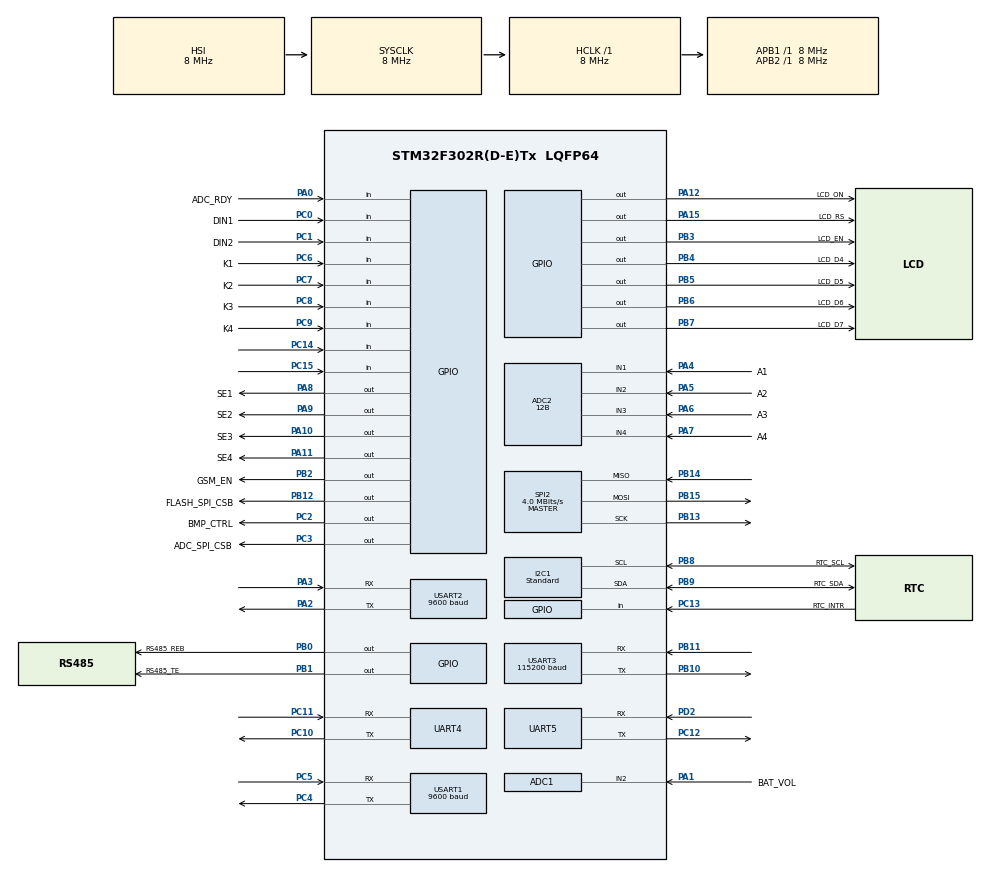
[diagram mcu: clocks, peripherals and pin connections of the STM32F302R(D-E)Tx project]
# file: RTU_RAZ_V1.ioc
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ADC1.Channel-0\#ChannelRegularConversion=ADC_CHANNEL_2
ADC1.ClockPrescaler=ADC_CLOCK_ASYNC_DIV1
ADC1.ContinuousConvMode=DISABLE
ADC1.DMAContinuousRequests=DISABLE
ADC1.DataAlign=ADC_DATAALIGN_RIGHT
ADC1.DiscontinuousConvMode=DISABLE
ADC1.EOCSelection=ADC_EOC_SINGLE_CONV
ADC1.EnableAnalogWatchDog1=false
ADC1.EnableAnalogWatchDog2=false
ADC1.EnableAnalogWatchDog3=false
ADC1.EnableInjectedConversion=ENABLE
ADC1.EnableRegularConversion=ENABLE
ADC1.ExternalTrigConv=ADC_SOFTWARE_START
ADC1.ExternalTrigConvEdge=ADC_EXTERNALTRIGCONVEDGE_NONE
ADC1.InjNumberOfConversion=0
ADC1.LowPowerAutoWait=DISABLE
ADC1.NbrOfConversion=1
ADC1.NbrOfConversionFlag=1
ADC1.Offset-0\#ChannelRegularConversion=0
ADC1.OffsetNumber-0\#ChannelRegularConversion=ADC_OFFSET_NONE
ADC1.Overrun=ADC_OVR_DATA_OVERWRITTEN
ADC1.Rank-0\#ChannelRegularConversion=1
ADC1.Resolution=ADC_RESOLUTION_12B
ADC1.SamplingTime-0\#ChannelRegularConversion=ADC_SAMPLETIME_1CYCLE_5
ADC1.ScanConvMode=ADC_SCAN_DISABLE
ADC1.master=1
ADC2.Channel-0\#ChannelRegularConversion=ADC_CHANNEL_1
ADC2.ClockPrescaler=ADC_CLOCK_ASYNC_DIV1
ADC2.ContinuousConvMode=DISABLE
ADC2.DMAContinuousRequests=DISABLE
ADC2.DataAlign=ADC_DATAALIGN_RIGHT
ADC2.DiscontinuousConvMode=DISABLE
ADC2.EOCSelection=ADC_EOC_SINGLE_CONV
ADC2.EnableAnalogWatchDog1=false
ADC2.EnableAnalogWatchDog2=false
ADC2.EnableAnalogWatchDog3=false
ADC2.EnableInjectedConversion=ENABLE
ADC2.EnableRegularConversion=ENABLE
ADC2.ExternalTrigConv=ADC_SOFTWARE_START
ADC2.ExternalTrigConvEdge=ADC_EXTERNALTRIGCONVEDGE_NONE
ADC2.InjNumberOfConversion=0
ADC2.LowPowerAutoWait=DISABLE
ADC2.NbrOfConversion=1
ADC2.NbrOfConversionFlag=1
ADC2.Offset-0\#ChannelRegularConversion=0
ADC2.OffsetNumber-0\#ChannelRegularConversion=ADC_OFFSET_NONE
ADC2.Overrun=ADC_OVR_DATA_OVERWRITTEN
ADC2.Rank-0\#ChannelRegularConversion=1
ADC2.Resolution=ADC_RESOLUTION_12B
ADC2.SamplingTime-0\#ChannelRegularConversion=ADC_SAMPLETIME_1CYCLE_5
ADC2.ScanConvMode=ADC_SCAN_DISABLE
FREERTOS.Tasks01=defaultTask,0,128,StartDefaultTask,Default,NULL,Dynamic,NULL,NULL;CommonTask,0,128,StartCommonTask,Default,NULL,Dynamic,NULL,NULL;GsmTask,0,128,StartGsmTask,Default,NULL,Dynamic,NULL,NULL
I2C1.I2C_Speed_Mode=I2C_Standard
I2C1.Timing=0x2000090E
Mcu.Family=STM32F3
Mcu.Name=STM32F302R(D-E)Tx
Mcu.Package=LQFP64
NVIC.PriorityGroup=NVIC_PRIORITYGROUP_4
NVIC.TIM1_UP_TIM16_IRQn=true\:0\:0\:false\:false\:true\:false\:false
NVIC.TimeBase=TIM1_UP_TIM16_IRQn
NVIC.TimeBaseIP=TIM16
PA0.GPIO_Label=ADC_RDY
PA0.Signal=GPIO_Input
PA1.GPIO_Label=BAT_VOL
PA1.Signal=SharedAnalog_PA1
PA10.GPIO_Label=SE3
PA10.Signal=GPIO_Output
PA11.GPIO_Label=SE4
PA11.Signal=GPIO_Output
PA12.GPIO_Label=LCD_ON
PA12.Signal=GPIO_Output
PA13.Mode=Serial_Wire
PA13.Signal=SYS_JTMS-SWDIO
PA14.Mode=Serial_Wire
PA14.Signal=SYS_JTCK-SWCLK
PA15.GPIO_Label=LCD_RS
PA15.Signal=GPIO_Output
PA2.Mode=Asynchronous
PA2.Signal=USART2_TX
PA3.Mode=Asynchronous
PA3.Signal=USART2_RX
PA4.GPIO_Label=A1
PA4.Signal=SharedAnalog_PA4
PA5.GPIO_Label=A2
PA5.Signal=SharedAnalog_PA5
PA6.GPIO_Label=A3
PA6.Signal=SharedAnalog_PA6
PA7.GPIO_Label=A4
PA7.Signal=SharedAnalog_PA7
PA8.GPIO_Label=SE1
PA8.Signal=GPIO_Output
PA9.GPIO_Label=SE2
PA9.Signal=GPIO_Output
PB0.GPIO_Label=RS485_REB
PB0.Signal=GPIO_Output
PB1.GPIO_Label=RS485_TE
PB1.Signal=GPIO_Output
PB10.Mode=Asynchronous
PB10.Signal=USART3_TX
PB11.Mode=Asynchronous
PB11.Signal=USART3_RX
PB12.GPIO_Label=FLASH_SPI_CSB
PB12.Signal=GPIO_Output
PB13.Mode=Full_Duplex_Master
PB13.Signal=SPI2_SCK
PB14.Mode=Full_Duplex_Master
PB14.Signal=SPI2_MISO
PB15.Mode=Full_Duplex_Master
PB15.Signal=SPI2_MOSI
PB2.GPIO_Label=GSM_EN
PB2.GPIO_ModeDefaultOutputPP=GPIO_MODE_OUTPUT_OD
PB2.GPIO_Speed=GPIO_SPEED_FREQ_LOW
PB2.PinState=GPIO_PIN_SET
PB2.Signal=GPIO_Output
PB3.GPIO_Label=LCD_EN
PB3.GPIO_ModeDefaultOutputPP=GPIO_MODE_OUTPUT_PP
PB3.Signal=GPIO_Output
PB4.GPIO_Label=LCD_D4
PB4.Signal=GPIO_Output
PB5.GPIO_Label=LCD_D5
PB5.Signal=GPIO_Output
PB6.GPIO_Label=LCD_D6
PB6.Signal=GPIO_Output
PB7.GPIO_Label=LCD_D7
PB7.Signal=GPIO_Output
PB8.GPIO_Label=RTC_SCL
PB8.Mode=I2C
PB8.Signal=I2C1_SCL
PB9.GPIO_Label=RTC_SDA
PB9.Mode=I2C
PB9.Signal=I2C1_SDA
PC0.GPIO_Label=DIN1
PC0.GPIO_PuPd=GPIO_PULLUP
PC0.Signal=GPIO_Input
PC1.GPIO_Label=DIN2
PC1.GPIO_PuPd=GPIO_PULLUP
PC1.Signal=GPIO_Input
PC10.Mode=Asynchronous
PC10.Signal=UART4_TX
PC11.Mode=Asynchronous
PC11.Signal=UART4_RX
PC12.Mode=Asynchronous
PC12.Signal=UART5_TX
PC13.GPIO_Label=RTC_INTR
PC13.GPIO_PuPd=GPIO_PULLUP
PC13.Signal=GPIO_Input
PC14-OSC32_IN.Signal=GPIO_Input
PC15-OSC32_OUT.Signal=GPIO_Input
PC2.GPIO_Label=BMP_CTRL
PC2.Signal=GPIO_Output
PC3.GPIO_Label=ADC_SPI_CSB
PC3.Signal=GPIO_Output
PC4.Mode=Asynchronous
PC4.Signal=USART1_TX
PC5.Mode=Asynchronous
PC5.Signal=USART1_RX
PC6.GPIO_Label=K1
PC6.GPIO_PuPd=GPIO_PULLUP
PC6.Signal=GPIO_Input
PC7.GPIO_Label=K2
PC7.GPIO_PuPd=GPIO_PULLUP
PC7.Signal=GPIO_Input
PC8.GPIO_Label=K3
PC8.GPIO_PuPd=GPIO_PULLUP
PC8.Signal=GPIO_Input
PC9.GPIO_Label=K4
PC9.GPIO_PuPd=GPIO_PULLUP
PC9.Signal=GPIO_Input
PD2.Mode=Asynchronous
PD2.Signal=UART5_RX
ProjectManager.HeapSize=0x200
ProjectManager.StackSize=0x400
ProjectManager.TargetToolchain=TrueSTUDIO
RCC.AHBFreq_Value=8000000
RCC.APB1Freq_Value=8000000
RCC.APB1TimFreq_Value=8000000
RCC.APB2Freq_Value=8000000
RCC.APB2TimFreq_Value=8000000
RCC.CortexFreq_Value=8000000
RCC.HCLKFreq_Value=8000000
RCC.HSE_VALUE=8000000
RCC.HSI_VALUE=8000000
RCC.LSE_VALUE=32768
RCC.SYSCLKFreq_VALUE=8000000
RCC.USBFreq_Value=16000000
SH.SharedAnalog_PA1.0=GPIO_Analog
SH.SharedAnalog_PA1.1=ADC1_IN2,IN2-Single-Ended
SH.SharedAnalog_PA4.0=GPIO_Analog
SH.SharedAnalog_PA4.1=ADC2_IN1,IN1-Single-Ended
SH.SharedAnalog_PA5.0=GPIO_Analog
SH.SharedAnalog_PA5.1=ADC2_IN2,IN2-Single-Ended
SH.SharedAnalog_PA6.0=GPIO_Analog
SH.SharedAnalog_PA6.1=ADC2_IN3,IN3-Single-Ended
SH.SharedAnalog_PA7.0=GPIO_Analog
SH.SharedAnalog_PA7.1=ADC2_IN4,IN4-Single-Ended
SPI2.CalculateBaudRate=4.0 MBits/s
SPI2.Direction=SPI_DIRECTION_2LINES
SPI2.Mode=SPI_MODE_MASTER
SPI2.VirtualType=VM_MASTER
USART1.BaudRate=9600
USART1.VirtualMode-Asynchronous=VM_ASYNC
USART2.BaudRate=9600
USART2.VirtualMode-Asynchronous=VM_ASYNC
USART3.BaudRate=115200
USART3.VirtualMode-Asynchronous=VM_ASYNC
VP_ADC1_TempSens_Input.Mode=IN-TempSens
VP_FREERTOS_VS_ENABLE.Mode=Enabled
VP_IWDG_VS_IWDG.Mode=IWDG_Activate
VP_SYS_VS_tim16.Mode=TIM16
board=custom

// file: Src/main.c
/**
  ******************************************************************************
  * @file           : main.c
  * @brief          : Main program body
  ******************************************************************************
  * This notice applies to any and all portions of this file
  * that are not between comment pairs USER CODE BEGIN and
  * USER CODE END. Other portions of this file, whether
  * inserted by the user or by software development tools
  * are owned by their respective copyright owners.
  *
  * Copyright (c) 2018 STMicroelectronics International N.V.
  * All rights reserved.
  *
  * Redistribution and use in source and binary forms, with or without
  * modification, are permitted, provided that the following conditions are met:
  *
  * 1. Redistribution of source code must retain the above copyright notice,
  *    this list of conditions and the following disclaimer.
  * 2. Redistributions in binary form must reproduce the above copyright notice,
  *    this list of conditions and the following disclaimer in the documentation
  *    and/or other materials provided with the distribution.
  * 3. Neither the name of STMicroelectronics nor the names of other
  *    contributors to this software may be used to endorse or promote products
  *    derived from this software without specific written permission.
  * 4. This software, including modifications and/or derivative works of this
  *    software, must execute solely and exclusively on microcontroller or
  *    microprocessor devices manufactured by or for STMicroelectronics.
  * 5. Redistribution and use of this software other than as permitted under
  *    this license is void and will automatically terminate your rights under
  *    this license.
  *
  * THIS SOFTWARE IS PROVIDED BY STMICROELECTRONICS AND CONTRIBUTORS "AS IS"
  * AND ANY EXPRESS, IMPLIED OR STATUTORY WARRANTIES, INCLUDING, BUT NOT
  * LIMITED TO, THE IMPLIED WARRANTIES OF MERCHANTABILITY, FITNESS FOR A
  * PARTICULAR PURPOSE AND NON-INFRINGEMENT OF THIRD PARTY INTELLECTUAL PROPERTY
  * RIGHTS ARE DISCLAIMED TO THE FULLEST EXTENT PERMITTED BY LAW. IN NO EVENT
  * SHALL STMICROELECTRONICS OR CONTRIBUTORS BE LIABLE FOR ANY DIRECT, INDIRECT,
  * INCIDENTAL, SPECIAL, EXEMPLARY, OR CONSEQUENTIAL DAMAGES (INCLUDING, BUT NOT
  * LIMITED TO, PROCUREMENT OF SUBSTITUTE GOODS OR SERVICES; LOSS OF USE, DATA,
  * OR PROFITS; OR BUSINESS INTERRUPTION) HOWEVER CAUSED AND ON ANY THEORY OF
  * LIABILITY, WHETHER IN CONTRACT, STRICT LIABILITY, OR TORT (INCLUDING
  * NEGLIGENCE OR OTHERWISE) ARISING IN ANY WAY OUT OF THE USE OF THIS SOFTWARE,
  * EVEN IF ADVISED OF THE POSSIBILITY OF SUCH DAMAGE.
  *
  ******************************************************************************
  */
#include "main.h"
#include "stm32f3xx_hal.h"
#include "cmsis_os.h"
#include "adc.h"
#include "i2c.h"
#include "iwdg.h"
#include "spi.h"
#include "usart.h"
#include "gpio.h"

/* USER CODE BEGIN Includes */
#include "common.h"
/* USER CODE END Includes */

/* USER CODE BEGIN PV */
/* Private variables ---------------------------------------------------------*/

/* USER CODE END PV */

void SystemClock_Config(void);
void MX_FREERTOS_Init(void);

/* USER CODE BEGIN PFP */
/* Private function prototypes -----------------------------------------------*/

/* USER CODE END PFP */

int main(void)
{

  /* MCU Configuration----------------------------------------------------------*/

  /* Reset of all peripherals, Initializes the Flash interface and the Systick. */
  HAL_Init();

  /* Configure the system clock */
  SystemClock_Config();

  /* Initialize all configured peripherals */
  MX_GPIO_Init();
  MX_IWDG_Init();
  MX_SPI2_Init();
  MX_UART4_Init();
  MX_UART5_Init();
  MX_USART1_UART_Init();
  MX_USART2_UART_Init();
  MX_USART3_UART_Init();
  MX_I2C1_Init();
  MX_ADC1_Init();
  MX_ADC2_Init();

  /* Call init function for freertos objects (in freertos.c) */
  MX_FREERTOS_Init();

  /* Start scheduler */
  osKernelStart();

  /* We should never get here as control is now taken by the scheduler */

  /* Infinite loop */
  while (1)
  {

  }

}

void SystemClock_Config(void)
{

  RCC_OscInitTypeDef RCC_OscInitStruct;
  RCC_ClkInitTypeDef RCC_ClkInitStruct;
  RCC_PeriphCLKInitTypeDef PeriphClkInit;

    /**Initializes the CPU, AHB and APB busses clocks
    */
  RCC_OscInitStruct.OscillatorType = RCC_OSCILLATORTYPE_HSI|RCC_OSCILLATORTYPE_LSI;
  RCC_OscInitStruct.HSIState = RCC_HSI_ON;
  RCC_OscInitStruct.HSICalibrationValue = 16;
  RCC_OscInitStruct.LSIState = RCC_LSI_ON;
  RCC_OscInitStruct.PLL.PLLState = RCC_PLL_ON;
  RCC_OscInitStruct.PLL.PLLSource = RCC_PLLSOURCE_HSI;
  RCC_OscInitStruct.PLL.PLLMUL = RCC_PLL_MUL2;
  RCC_OscInitStruct.PLL.PREDIV = RCC_PREDIV_DIV1;
  if (HAL_RCC_OscConfig(&RCC_OscInitStruct) != HAL_OK)
  {
    _Error_Handler(__FILE__, __LINE__);
  }

    /**Initializes the CPU, AHB and APB busses clocks
    */
  RCC_ClkInitStruct.ClockType = RCC_CLOCKTYPE_HCLK|RCC_CLOCKTYPE_SYSCLK
                              |RCC_CLOCKTYPE_PCLK1|RCC_CLOCKTYPE_PCLK2;
  RCC_ClkInitStruct.SYSCLKSource = RCC_SYSCLKSOURCE_HSI;
  RCC_ClkInitStruct.AHBCLKDivider = RCC_SYSCLK_DIV1;
  RCC_ClkInitStruct.APB1CLKDivider = RCC_HCLK_DIV1;
  RCC_ClkInitStruct.APB2CLKDivider = RCC_HCLK_DIV1;

  if (HAL_RCC_ClockConfig(&RCC_ClkInitStruct, FLASH_LATENCY_0) != HAL_OK)
  {
    _Error_Handler(__FILE__, __LINE__);
  }

  PeriphClkInit.PeriphClockSelection = RCC_PERIPHCLK_USART1|RCC_PERIPHCLK_USART2
                              |RCC_PERIPHCLK_USART3|RCC_PERIPHCLK_UART4
                              |RCC_PERIPHCLK_UART5|RCC_PERIPHCLK_I2C1
                              |RCC_PERIPHCLK_ADC12;
  PeriphClkInit.Usart1ClockSelection = RCC_USART1CLKSOURCE_PCLK2;
  PeriphClkInit.Usart2ClockSelection = RCC_USART2CLKSOURCE_PCLK1;
  PeriphClkInit.Usart3ClockSelection = RCC_USART3CLKSOURCE_PCLK1;
  PeriphClkInit.Uart4ClockSelection = RCC_UART4CLKSOURCE_PCLK1;
  PeriphClkInit.Uart5ClockSelection = RCC_UART5CLKSOURCE_PCLK1;
  PeriphClkInit.Adc12ClockSelection = RCC_ADC12PLLCLK_DIV1;
  PeriphClkInit.I2c1ClockSelection = RCC_I2C1CLKSOURCE_HSI;
  if (HAL_RCCEx_PeriphCLKConfig(&PeriphClkInit) != HAL_OK)
  {
    _Error_Handler(__FILE__, __LINE__);
  }

    /**Configure the Systick interrupt time
    */
  HAL_SYSTICK_Config(HAL_RCC_GetHCLKFreq()/1000);

    /**Configure the Systick
    */
  HAL_SYSTICK_CLKSourceConfig(SYSTICK_CLKSOURCE_HCLK);

  /* SysTick_IRQn interrupt configuration */
  HAL_NVIC_SetPriority(SysTick_IRQn, 15, 0);
}

void HAL_TIM_PeriodElapsedCallback(TIM_HandleTypeDef *htim)
{
  if (htim->Instance == TIM16) {
    HAL_IncTick();
  }
}

void _Error_Handler(char *file, int line)
{
  while(1)
  {
  }
}

/************************ (C) COPYRIGHT STMicroelectronics *****END OF FILE****/

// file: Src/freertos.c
/**
  ******************************************************************************
  * File Name          : freertos.c
  * Description        : Code for freertos applications
  ******************************************************************************
  * This notice applies to any and all portions of this file
  * that are not between comment pairs USER CODE BEGIN and
  * USER CODE END. Other portions of this file, whether
  * inserted by the user or by software development tools
  * are owned by their respective copyright owners.
  *
  * Copyright (c) 2018 STMicroelectronics International N.V.
  * All rights reserved.
  *
  * Redistribution and use in source and binary forms, with or without
  * modification, are permitted, provided that the following conditions are met:
  *
  * 1. Redistribution of source code must retain the above copyright notice,
  *    this list of conditions and the following disclaimer.
  * 2. Redistributions in binary form must reproduce the above copyright notice,
  *    this list of conditions and the following disclaimer in the documentation
  *    and/or other materials provided with the distribution.
  * 3. Neither the name of STMicroelectronics nor the names of other
  *    contributors to this software may be used to endorse or promote products
  *    derived from this software without specific written permission.
  * 4. This software, including modifications and/or derivative works of this
  *    software, must execute solely and exclusively on microcontroller or
  *    microprocessor devices manufactured by or for STMicroelectronics.
  * 5. Redistribution and use of this software other than as permitted under
  *    this license is void and will automatically terminate your rights under
  *    this license.
  *
  * THIS SOFTWARE IS PROVIDED BY STMICROELECTRONICS AND CONTRIBUTORS "AS IS"
  * AND ANY EXPRESS, IMPLIED OR STATUTORY WARRANTIES, INCLUDING, BUT NOT
  * LIMITED TO, THE IMPLIED WARRANTIES OF MERCHANTABILITY, FITNESS FOR A
  * PARTICULAR PURPOSE AND NON-INFRINGEMENT OF THIRD PARTY INTELLECTUAL PROPERTY
  * RIGHTS ARE DISCLAIMED TO THE FULLEST EXTENT PERMITTED BY LAW. IN NO EVENT
  * SHALL STMICROELECTRONICS OR CONTRIBUTORS BE LIABLE FOR ANY DIRECT, INDIRECT,
  * INCIDENTAL, SPECIAL, EXEMPLARY, OR CONSEQUENTIAL DAMAGES (INCLUDING, BUT NOT
  * LIMITED TO, PROCUREMENT OF SUBSTITUTE GOODS OR SERVICES; LOSS OF USE, DATA,
  * OR PROFITS; OR BUSINESS INTERRUPTION) HOWEVER CAUSED AND ON ANY THEORY OF
  * LIABILITY, WHETHER IN CONTRACT, STRICT LIABILITY, OR TORT (INCLUDING
  * NEGLIGENCE OR OTHERWISE) ARISING IN ANY WAY OUT OF THE USE OF THIS SOFTWARE,
  * EVEN IF ADVISED OF THE POSSIBILITY OF SUCH DAMAGE.
  *
  ******************************************************************************
  */

#include "FreeRTOS.h"
#include "task.h"
#include "cmsis_os.h"

/* USER CODE BEGIN Includes */
#include "common.h"
#include "usart.h"
/* USER CODE END Includes */

osThreadId defaultTaskHandle;
osThreadId CommonTaskHandle;
osThreadId GsmTaskHandle;

void StartDefaultTask(void const * argument);
void StartCommonTask(void const * argument);
void StartGsmTask(void const * argument);

void MX_FREERTOS_Init(void); /* (MISRA C 2004 rule 8.1) */

/* Hook prototypes */

/* Init FreeRTOS */

void MX_FREERTOS_Init(void) {

  /* Create the thread(s) */
  /* definition and creation of defaultTask */
  osThreadDef(defaultTask, StartDefaultTask, osPriorityNormal, 0, 128);
  defaultTaskHandle = osThreadCreate(osThread(defaultTask), NULL);

  /* definition and creation of CommonTask */
  osThreadDef(CommonTask, StartCommonTask, osPriorityNormal, 0, 128);
  CommonTaskHandle = osThreadCreate(osThread(CommonTask), NULL);

  /* definition and creation of GsmTask */
  osThreadDef(GsmTask, StartGsmTask, osPriorityNormal, 0, 128);
  GsmTaskHandle = osThreadCreate(osThread(GsmTask), NULL);

}

/* StartDefaultTask function */
void StartDefaultTask(void const * argument)
{

  /* USER CODE BEGIN StartDefaultTask */
  /* Infinite loop */
	osDelay(1);
  for(;;)
  {
    Uartprint(3,(U8 *)"Task1 hisdsd\r\n");
    osDelay(1000);
  }
  /* USER CODE END StartDefaultTask */
}

/* StartCommonTask function */
void StartCommonTask(void const * argument)
{
  /* USER CODE BEGIN StartCommonTask */
  /* Infinite loop */
	osDelay(1);
  for(;;)
  {
	  Uartprint(3,(U8 *)"Task2\r\n");
	  osDelay(1500);
  }
  /* USER CODE END StartCommonTask */
}

/* StartGsmTask function */
void StartGsmTask(void const * argument)
{
  /* USER CODE BEGIN StartGsmTask */
  /* Infinite loop */
	osDelay(1);
  for(;;)
  {
	  Uartprint(3,(U8 *)"Task3\r\n");
	  osDelay(2000);
  }
  /* USER CODE END StartGsmTask */
}

/************************ (C) COPYRIGHT STMicroelectronics *****END OF FILE****/
